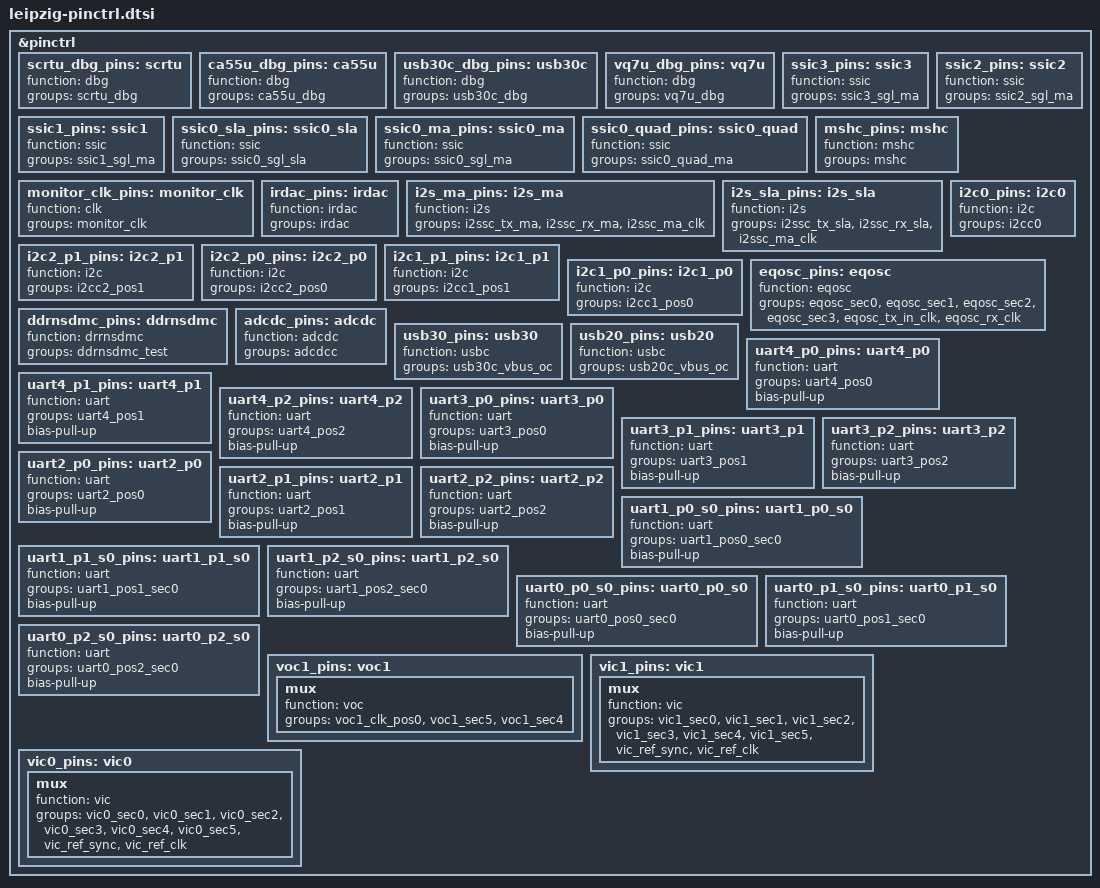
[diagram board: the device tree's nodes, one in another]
// SPDX-License-Identifier: (GPL-2.0 OR MIT)
/*
 * Copyright (C) 2021 VATICS Inc.
 */

#include "leipzig.dtsi"


&pinctrl {
	scrtu_dbg_pins: scrtu {
		function = "dbg";
		groups = "scrtu_dbg";
	};

	ca55u_dbg_pins: ca55u {
		function = "dbg";
		groups = "ca55u_dbg";
	};

	usb30c_dbg_pins: usb30c {
		function = "dbg";
		groups = "usb30c_dbg";
	};

	vq7u_dbg_pins: vq7u {
		function = "dbg";
		groups = "vq7u_dbg";
	};

	ssic3_pins: ssic3 {
		function = "ssic";
		groups = "ssic3_sgl_ma";
	};

	ssic2_pins: ssic2 {
		function = "ssic";
		groups = "ssic2_sgl_ma";
	};

	ssic1_pins: ssic1 {
		function = "ssic";
		groups = "ssic1_sgl_ma";
	};

	ssic0_sla_pins: ssic0_sla {
		function = "ssic";
		groups = "ssic0_sgl_sla";
	};

	ssic0_ma_pins: ssic0_ma {
		function = "ssic";
		groups = "ssic0_sgl_ma";
	};

	ssic0_quad_pins: ssic0_quad {
		function = "ssic";
		groups = "ssic0_quad_ma";
	};

	mshc_pins: mshc {
		function = "mshc";
		groups = "mshc";
	};

	monitor_clk_pins: monitor_clk {
		function = "clk";
		groups = "monitor_clk";
	};

	irdac_pins: irdac {
		function = "irdac";
		groups = "irdac";
	};

	i2s_ma_pins: i2s_ma {
		function = "i2s";
		groups = "i2ssc_tx_ma", "i2ssc_rx_ma",
			"i2ssc_ma_clk";
	};

	i2s_sla_pins: i2s_sla {
		function = "i2s";
		groups = "i2ssc_tx_sla", "i2ssc_rx_sla",
			"i2ssc_ma_clk";
	};

	i2c2_p1_pins: i2c2_p1 {
		function = "i2c";
		groups = "i2cc2_pos1";
	};

	i2c2_p0_pins: i2c2_p0 {
		function = "i2c";
		groups = "i2cc2_pos0";
	};

	i2c1_p1_pins: i2c1_p1 {
		function = "i2c";
		groups = "i2cc1_pos1";
	};

	i2c1_p0_pins: i2c1_p0 {
		function = "i2c";
		groups = "i2cc1_pos0";
	};

	i2c0_pins: i2c0 {
		function = "i2c";
		groups = "i2cc0";
	};

	eqosc_pins: eqosc {
		function = "eqosc";
		groups = "eqosc_sec0", "eqosc_sec1",
			"eqosc_sec2", "eqosc_sec3",
			"eqosc_tx_in_clk", "eqosc_rx_clk";
	};

	ddrnsdmc_pins: ddrnsdmc {
		function = "drrnsdmc";
		groups = "ddrnsdmc_test";
	};

	adcdc_pins: adcdc {
		function = "adcdc";
		groups = "adcdcc";
	};

	usb30_pins: usb30 {
		function = "usbc";
		groups = "usb30c_vbus_oc";
		/* groups = "usb30c_vbus_oc", "usb30c_drv_vbus"; */
	};

	usb20_pins: usb20 {
		function = "usbc";
		groups = "usb20c_vbus_oc";
		/* groups = "usb20c_vbus_oc", "usb20c_drv_vbus"; */
	};

	uart4_p0_pins: uart4_p0 {
		function = "uart";
		groups = "uart4_pos0";
		bias-pull-up;
	};

	uart4_p1_pins: uart4_p1 {
		function = "uart";
		groups = "uart4_pos1";
		bias-pull-up;
	};

	uart4_p2_pins: uart4_p2 {
		function = "uart";
		groups = "uart4_pos2";
		bias-pull-up;
	};

	uart3_p0_pins: uart3_p0 {
		function = "uart";
		groups = "uart3_pos0";
		bias-pull-up;
	};

	uart3_p1_pins: uart3_p1 {
		function = "uart";
		groups = "uart3_pos1";
		bias-pull-up;
	};

	uart3_p2_pins: uart3_p2 {
		function = "uart";
		groups = "uart3_pos2";
		bias-pull-up;
	};

	uart2_p0_pins: uart2_p0 {
		function = "uart";
		groups = "uart2_pos0";
		bias-pull-up;
	};

	uart2_p1_pins: uart2_p1 {
		function = "uart";
		groups = "uart2_pos1";
		bias-pull-up;
	};

	uart2_p2_pins: uart2_p2 {
		function = "uart";
		groups = "uart2_pos2";
		bias-pull-up;
	};

	uart1_p0_s0_pins: uart1_p0_s0 {
		function = "uart";
		groups = "uart1_pos0_sec0";
		bias-pull-up;
	};

	uart1_p1_s0_pins: uart1_p1_s0 {
		function = "uart";
		groups = "uart1_pos1_sec0";
		bias-pull-up;
	};

	uart1_p2_s0_pins: uart1_p2_s0 {
		function = "uart";
		groups = "uart1_pos2_sec0";
		bias-pull-up;
	};

	uart0_p0_s0_pins: uart0_p0_s0 {
		function = "uart";
		groups = "uart0_pos0_sec0";
		bias-pull-up;
	};

	uart0_p1_s0_pins: uart0_p1_s0 {
		function = "uart";
		groups = "uart0_pos1_sec0";
		bias-pull-up;
	};

	uart0_p2_s0_pins: uart0_p2_s0 {
		function = "uart";
		groups = "uart0_pos2_sec0";
		bias-pull-up;
	};

	voc1_pins: voc1 {
		mux {
			function = "voc";
			groups = "voc1_clk_pos0", "voc1_sec5", "voc1_sec4";
			/*
			drive-strength = <8>;
			slew-rate-enable;
			input-schmitt-enable;
			*/
		};
		/*
		conf-clk {
			pins = "INOUT_85";
			bias-pull-down;
		};
		*/
	};

	vic1_pins: vic1 {
		mux {
			function = "vic";
			groups = "vic1_sec0", "vic1_sec1", "vic1_sec2",
				"vic1_sec3", "vic1_sec4", "vic1_sec5",
				"vic_ref_sync", "vic_ref_clk";
		};
	};

	vic0_pins: vic0 {
		mux {
			function = "vic";
			groups = "vic0_sec0", "vic0_sec1", "vic0_sec2",
				"vic0_sec3", "vic0_sec4", "vic0_sec5",
				"vic_ref_sync", "vic_ref_clk";
		};
	};

};

